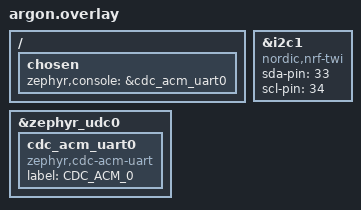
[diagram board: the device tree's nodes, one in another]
/*
 *
 * Overlay
 *
 *
 */
/ {
	chosen {
			zephyr,console = &cdc_acm_uart0;
	};
};

&zephyr_udc0 {
	cdc_acm_uart0: cdc_acm_uart0 {
			compatible = "zephyr,cdc-acm-uart";
			label = "CDC_ACM_0";
	};
};


 &i2c1 {
     compatible = "nordic,nrf-twi";
     status = "okay";
     sda-pin = <33>;
     scl-pin = <34>;
 };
